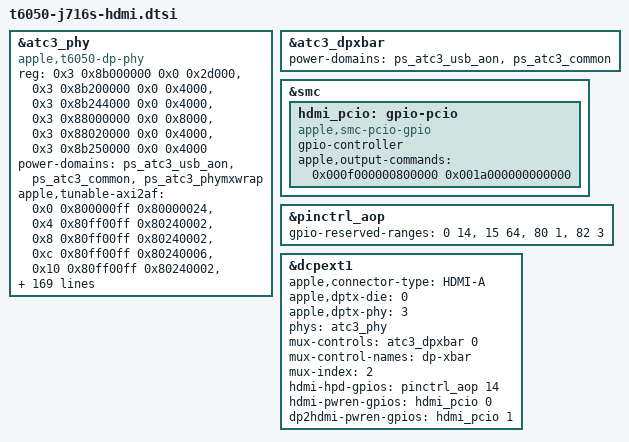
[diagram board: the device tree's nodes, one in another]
// SPDX-License-Identifier: GPL-2.0+ OR MIT
/*
 * J716s HDMI port (ADT port-hdmi0): dcpext1 drives ATC3 as a fixed four-lane DisplayPort PHY
 * into the on-board DP-to-HDMI converter (/arm-io/i2c8/pcon0), the shape of the M4 Pro's
 * t6040-j614s-extdisp-hdmi.dtsi on T6050's parts. Only t6050-j716s-hdmi.dts includes it; the
 * everyday t6050-j716s.dtb is unchanged.
 *
 * From the J716s's macOS 27.3 device tree:
 *   dcpext1      dp-switch-ufp-endpoint 1, port 0: the HDMI engine (display-crossbar0)
 *   atc3-dpphy   port-type 6 (HDMI), dp-switch-dfp-endpoint 3, dp2hdmi-gpio-parent
 *   atc-phy3     port-type 6, atc-lane-config <3 3>, no usb-drd3: a DP-only PHY
 *   dp2hdmi-gpio0  function-hdmi_hpd       AOP GPIO 14 (also its interrupt)
 *                  function-force-dpfu     AOP GPIO 15 (the converter's firmware update; never touched)
 *                  function-hdmi_pwr_en    pKW8('pcIO', 0x800000, 0xf0000)
 *                  function-dp2hdmi_pwr_en pKW8('pcIO', 0x0, 0x1a0000)
 *   i2c8/pcon0   address 0x08, no compatible, no interrupt: not described, as on the J614 and J616
 *
 * Nothing here runs unless the boot loader hands dcpext1 over (on the 27.3 beta, aura hands the
 * external engines over only when the command line asks for them). The PHY, the crossbar and the
 * pcIO outputs probe at boot without driving anything: the crossbar holds ATC3's always-on and
 * common power states from its probe, as the ATC1 and ATC2 crossbars do theirs.
 */

/*
 * ATC3: the binding's fixed apple,t6050-dp-phy (no Type-C switches, no PHY firmware): /arm-io/
 * atc-phy3 reg[2] (core, to the end of bank 35) and reg[39]..[43] (reset, fabric, axi2af, lioa,
 * common-cfg); the usb-aon, common and wrapper states. The boot loader copies ATC tunables only
 * for Type-C combo PHYs, so this PHY's are the ADT's, read from this machine's macOS 27.3 device
 * tree (atc-phy3; offset in the low 24 bits, the 0x20 size byte dropped). The DP training tables
 * are the driver's defaults. usb-drd3 and its DARTs, which this board does not have, go.
 */
/delete-node/ &usb_drd3;
/delete-node/ &usb_drd3_dart_0;
/delete-node/ &usb_drd3_dart_1;

&atc3_phy {
	compatible = "apple,t6050-dp-phy";
	reg = <0x3 0x8b000000 0x0 0x2d000>,
	      <0x3 0x8b200000 0x0 0x4000>,
	      <0x3 0x8b244000 0x0 0x4000>,
	      <0x3 0x88000000 0x0 0x8000>,
	      <0x3 0x88020000 0x0 0x4000>,
	      <0x3 0x8b250000 0x0 0x4000>;
	reg-names = "core", "reset", "fabric", "axi2af", "lioa", "common-cfg";
	#phy-cells = <0>;
	/delete-property/ #reset-cells;
	/delete-property/ apple,port-index;
	/delete-property/ apple,guest-port-reserved;
	/delete-property/ mode-switch;
	/delete-property/ orientation-switch;
	/delete-property/ mboxes;
	power-domains = <&ps_atc3_usb_aon>, <&ps_atc3_common>, <&ps_atc3_phymxwrap>;
	power-domain-names = "usb-aon", "common", "wrapper";
	/* ADT tunable_ATC0AXI2AF */
	apple,tunable-axi2af = <0x0 0x800000ff 0x80000024>,
	                       <0x4 0x80ff00ff 0x80240002>,
	                       <0x8 0x80ff00ff 0x80240002>,
	                       <0xc 0x80ff00ff 0x80240006>,
	                       <0x10 0x80ff00ff 0x80240002>,
	                       <0x14 0x80ff00ff 0x80220004>,
	                       <0x18 0x80ff00ff 0x80240002>,
	                       <0x1c 0x80ff00ff 0x80240002>,
	                       <0x20 0x80ff00ff 0x80240002>,
	                       <0x24 0x800000ff 0x8000001b>,
	                       <0x28 0x800000ff 0x80000048>,
	                       <0x2c 0x80ff00ff 0x80480004>,
	                       <0x30 0x80ff00ff 0x80480004>,
	                       <0x34 0x80ff00ff 0x80440008>,
	                       <0x38 0x80ff00ff 0x80480004>,
	                       <0x3c 0x80ff00ff 0x80480004>,
	                       <0x40 0x800000ff 0x8000001b>,
	                       <0x44 0x800000ff 0x8000001b>,
	                       <0x48 0x800000ff 0x8000001e>,
	                       <0x100 0x000000ff 0x000000ff>,
	                       <0x104 0x00000003 0x00000003>,
	                       <0x300 0x00000003 0x00000001>,
	                       <0x304 0x3f3f0000 0x04040000>,
	                       <0x308 0x000003ff 0x0000000d>,
	                       <0x30c 0x700003ff 0x0000000c>,
	                       <0x310 0x0080001f 0x00800001>,
	                       <0x314 0x8080001f 0x80800001>,
	                       <0x318 0x0080001f 0x00800001>,
	                       <0x31c 0x8080001f 0x80800001>,
	                       <0x320 0x0080001f 0x00800003>,
	                       <0x324 0x8080001f 0x80800003>,
	                       <0x328 0x0080001f 0x00800003>,
	                       <0x32c 0x8080001f 0x80800003>,
	                       <0x330 0x0080001f 0x00800003>,
	                       <0x334 0x8080001f 0x80800003>,
	                       <0x338 0x0080001f 0x00800003>,
	                       <0x33c 0x0080001f 0x00800003>,
	                       <0x340 0x0080001f 0x00800003>,
	                       <0x344 0x0080001f 0x00800003>,
	                       <0x348 0x0080001f 0x00800003>,
	                       <0x34c 0x0080001f 0x00800003>,
	                       <0x350 0x0080001f 0x00800003>,
	                       <0x404 0xffff0023 0x001e0021>,
	                       <0x408 0x000003ff 0x0000000d>,
	                       <0x40c 0x700003ff 0x0000000c>,
	                       <0x410 0x8000001f 0x80000001>,
	                       <0x414 0x8000001f 0x80000001>,
	                       <0x418 0x8000001f 0x80000001>,
	                       <0x41c 0x8000001f 0x80000001>,
	                       <0x420 0x8000001f 0x80000003>,
	                       <0x424 0x8000001f 0x80000003>,
	                       <0x428 0x8000001f 0x80000003>,
	                       <0x42c 0x8000001f 0x80000003>,
	                       <0x430 0x8000001f 0x80000003>,
	                       <0x434 0x8000001f 0x80000003>,
	                       <0x438 0x8000001f 0x80000003>,
	                       <0x43c 0x8000001f 0x80000003>,
	                       <0x440 0x8000001f 0x80000003>,
	                       <0x444 0x8000001f 0x80000003>,
	                       <0x448 0x8000001f 0x80000003>,
	                       <0x44c 0x8000001f 0x80000003>,
	                       <0x450 0x8000001f 0x80000003>,
	                       <0x948 0x07ff07ff 0x00280000>,
	                       <0xa48 0x07ff07ff 0x00400040>,
	                       <0xb48 0x07ff07ff 0x00b8010e>,
	                       <0xc48 0x07ff07ff 0x00400020>,
	                       <0xd48 0x07ff07ff 0x008a008a>,
	                       <0x1000 0xffffffff 0x7fffffff>,
	                       <0x1004 0x00000100 0x00000100>,
	                       <0x4008 0x00000001 0x00000001>,
	                       <0x400c 0x00000001 0x00000001>,
	                       <0x4014 0x00000001 0x00000001>,
	                       <0x4018 0x00000001 0x00000000>,
	                       <0x401c 0x00000001 0x00000001>,
	                       <0x108 0xffff0007 0x00100001>;
	/* ADT tunable_ATC_FABRIC */
	apple,tunable-fabric = <0x4 0x003f003f 0x00200020>,
	                       <0xc 0x000000f1 0x000000a1>,
	                       <0x10 0x0000801f 0x00000004>,
	                       <0x18 0x003f003f 0x00200020>,
	                       <0x20 0x000000f1 0x000000a1>,
	                       <0x24 0x0000801f 0x00000004>,
	                       <0x2c 0x00ff00ff 0x00960096>,
	                       <0x34 0x000000f1 0x00000071>,
	                       <0x38 0x0000801f 0x00000004>,
	                       <0x40 0x0000003f 0x00000020>,
	                       <0x48 0x0000801f 0x00000004>,
	                       <0x50 0x007f007f 0x00450045>,
	                       <0x58 0x0000801f 0x00000004>,
	                       <0x60 0x0000003f 0x00000020>,
	                       <0x68 0x0000801f 0x00000004>,
	                       <0x70 0x00000001 0x00000001>,
	                       <0x74 0x0000801f 0x00000004>,
	                       <0x7c 0x007f007f 0x00400040>,
	                       <0x80 0x000000f1 0x00000011>,
	                       <0x84 0x00000001 0x00000001>,
	                       <0x88 0x00000001 0x00000001>,
	                       <0x8c 0x0000801f 0x00000004>,
	                       <0x94 0x003f003f 0x00240024>,
	                       <0x98 0x000000f1 0x00000011>,
	                       <0x9c 0x0000801f 0x00000004>,
	                       <0xa4 0x000001ff 0x000001e0>,
	                       <0xa8 0x0000801f 0x00000004>,
	                       <0xb0 0x0000003f 0x00000020>,
	                       <0xb8 0x0000801f 0x00000004>,
	                       <0xc0 0x0000003f 0x00000020>,
	                       <0xc8 0x0000801f 0x00000004>,
	                       <0xd0 0x001f001f 0x00100010>,
	                       <0xd8 0x00000001 0x00000001>,
	                       <0xdc 0x00000001 0x00000001>,
	                       <0xe0 0x0000801f 0x00000004>,
	                       <0xe8 0x0000000f 0x00000008>,
	                       <0xec 0x0000801f 0x00000004>,
	                       <0xf4 0xffffffff 0x01010101>,
	                       <0xf8 0x0000801f 0x00000004>,
	                       <0x100 0x00000001 0x00000001>,
	                       <0x104 0x00000001 0x00000001>,
	                       <0x108 0x0000801f 0x00000004>,
	                       <0x110 0x0000801f 0x00000004>,
	                       <0x118 0x0000801f 0x00000004>,
	                       <0x120 0x00000001 0x00000001>,
	                       <0x124 0x00000001 0x00000001>,
	                       <0x128 0x0000801f 0x00000004>,
	                       <0x130 0xffffffff 0x01010101>,
	                       <0x134 0x0000801f 0x00000004>,
	                       <0x13c 0x00000001 0x00000001>,
	                       <0x140 0x00000001 0x00000001>,
	                       <0x144 0x0000801f 0x00000004>,
	                       <0x14c 0x00000001 0x00000001>,
	                       <0x150 0x00000001 0x00000001>,
	                       <0x154 0x0000801f 0x00000004>,
	                       <0x15c 0x0000801f 0x00000004>,
	                       <0x164 0xffffffff 0x01010101>,
	                       <0x168 0x0000ffff 0x00000101>,
	                       <0x16c 0x0000801f 0x00000004>,
	                       <0x174 0x00000001 0x00000001>,
	                       <0x178 0x00000001 0x00000001>,
	                       <0x17c 0x0000801f 0x00000004>,
	                       <0x184 0x00000001 0x00000001>,
	                       <0x188 0x00000001 0x00000001>,
	                       <0x18c 0x0000801f 0x00000004>;
	/* ADT tunable_ATC_COMMON_CFG */
	apple,tunable-common-cfg = <0x8 0x00000001 0x00000001>;
	/* ADT tunable_ATC0AXI2AF_LIOA */
	apple,tunable-lioa = <0x28 0x0000fc2f 0x00000000>,
	                     <0x2c 0x00000007 0x00000000>,
	                     <0x30 0x000000ff 0x00000000>,
	                     <0x34 0x000003ff 0x00000000>,
	                     <0x58 0x0000030b 0x00000000>;
	/* ADT tunable_LN0_RX_CFG_TX_OF_RXCLK */
	apple,tunable-lane0-rx-clock = <0x94 0x00080000 0x00080000>,
	                               <0x98 0x00080000 0x00080000>,
	                               <0xa4 0x00800000 0x00800000>,
	                               <0xa8 0x00200000 0x00200000>;
	/* ADT tunable_LN1_RX_CFG_TX_OF_RXCLK */
	apple,tunable-lane1-rx-clock = <0x94 0x00080000 0x00080000>,
	                               <0x98 0x00080000 0x00080000>,
	                               <0xa4 0x00800000 0x00800000>,
	                               <0xa8 0x00200000 0x00200000>;
	/* ADT tunable_LN0_RX_EQ_DFLT */
	apple,tunable-lane0-rx-eq = <0x698 0x07e00000 0x04400000>,
	                            <0x6a0 0x07e00000 0x03800000>,
	                            <0x69c 0x07e00000 0x03800000>;
	/* ADT tunable_LN1_RX_EQ_DFLT */
	apple,tunable-lane1-rx-eq = <0x698 0x07e00000 0x04400000>,
	                            <0x6a0 0x07e00000 0x03800000>,
	                            <0x69c 0x07e00000 0x03800000>;
	/* ADT tunable_AUSPLL_CORE */
	apple,tunable-auspll = <0x24 0x00000c00 0x00000800>,
	                       <0x30 0x0000001f 0x0000000f>,
	                       <0x40 0x07d8007f 0x04000039>,
	                       <0xb0 0x0b800000 0x01800000>,
	                       <0xe8 0x00060001 0x00040001>,
	                       <0x138 0x0f800000 0x07800000>;
	status = "okay";
};

/* /arm-io/atc3-dpxbar: ATC3's display crossbar, powered as the ATC1 one is */
&atc3_dpxbar {
	power-domains = <&ps_atc3_usb_aon>, <&ps_atc3_common>;
	power-domain-names = "usb-aon", "common";
	status = "okay";
};

/*
 * The converter's two power enables, the SMC pcIO outputs of the ADT's dp2hdmi-gpio0, as
 * pKW8('pcIO', lo, hi) templates, (hi << 32) | lo: line 0 hdmi_pwr_en, line 1 dp2hdmi_pwr_en
 * (the J775D's order). t6050-j716s.dts dropped the SoC's pcIO node (its trackpad AFE reset uses
 * gp1c), so it comes back here under a name and label of its own.
 */
&smc {
	hdmi_pcio: gpio-pcio {
		compatible = "apple,smc-pcio-gpio";
		gpio-controller;
		#gpio-cells = <2>;
		apple,output-commands = /bits/ 64 <0x000f000000800000 0x001a000000000000>;
	};
};

/*
 * The AOP GPIOs this board exposes: the converter's hotplug (14) beside the two routers' LSTX
 * pins (79 and 81). Pin 15 (force-dpfu) stays reserved.
 */
&pinctrl_aop {
	gpio-reserved-ranges = <0 14>, <15 64>, <80 1>, <82 3>;
};

/*
 * dcpext1 as the fixed HDMI-A output: through ATC3's crossbar in state 2 (2 x ufp endpoint 1 +
 * port 0; crossbar control 0 feeds ATC3's DP PHY, dfp endpoint 3) into the PHY, dptx-phy 3 on
 * die 0. Its pairing role beside dcpext0 (t6050-j714s-display.dtsi) gives way to the HDMI port,
 * as macOS gives this engine to it. The hotplug and the two power enables as above.
 */
&dcpext1 {
	apple,connector-type = "HDMI-A";
	apple,dptx-die = <0>;
	apple,dptx-phy = <3>;
	phys = <&atc3_phy>;
	phy-names = "dp-phy";
	mux-controls = <&atc3_dpxbar 0>;
	mux-control-names = "dp-xbar";
	mux-index = <2>;
	hdmi-hpd-gpios = <&pinctrl_aop 14 GPIO_ACTIVE_HIGH>;
	hdmi-pwren-gpios = <&hdmi_pcio 0 GPIO_ACTIVE_HIGH>;
	dp2hdmi-pwren-gpios = <&hdmi_pcio 1 GPIO_ACTIVE_HIGH>;
};
